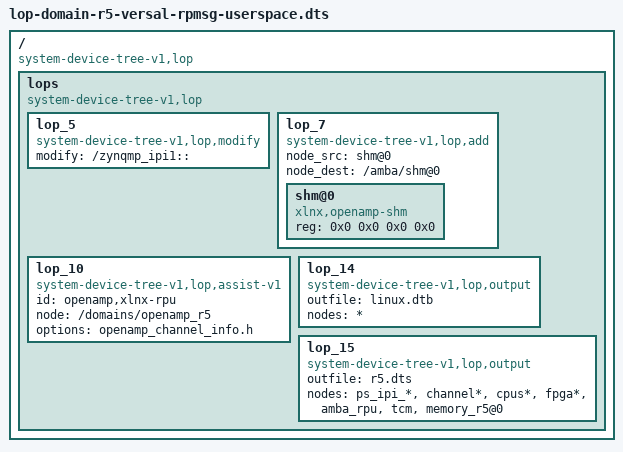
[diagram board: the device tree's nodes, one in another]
/*
 * Copyright (c) 2019,2020 Xilinx Inc. All rights reserved.
 *
 * Author:
 *       Bruce Ashfield <bruce.ashfield@xilinx.com>
 *
 * SPDX-License-Identifier: BSD-3-Clause
 */

/dts-v1/;

/ {
        compatible = "system-device-tree-v1,lop";
        lops {
                compatible = "system-device-tree-v1,lop";
                lop_5 {
                        // modify to "nothing", is a remove operation
                        compatible = "system-device-tree-v1,lop,modify";
                        modify = "/zynqmp_ipi1::";
                };

                lop_7 {
                        // node add
                        compatible = "system-device-tree-v1,lop,add";
                        node_src = "shm@0";
                        node_dest = "/amba/shm@0";
                        shm@0 {
                            compatible = "xlnx,openamp-shm";
                            #address-cells = <2>;
                            #size-cells = <2>;
                            ranges;
			    reg = <0x0 0x0 0x0 0x0>;
                        };
                  };
                  lop_10 {
                          // optionally execute a routine in a loaded module. If the routine
                          // isn't found, this is NOT a failure. Since we don't want to tightly
                          // couple these transforms and loaded modules
                          compatible = "system-device-tree-v1,lop,assist-v1";
                          id = "openamp,xlnx-rpu";
                          node = "/domains/openamp_r5";
                          options = "openamp_channel_info.h";
                  };

                  lop_14 {
                         compatible = "system-device-tree-v1,lop,output";
                         outfile = "linux.dtb";
                         // * is "all nodes"
                         nodes = "*";
                  };
                  lop_15 {
                         compatible = "system-device-tree-v1,lop,output";
                         outfile = "r5.dts";
                         // * is "all nodes"
                         nodes = "ps_ipi_*", "channel*", "cpus*","fpga*", "amba_rpu","tcm","memory_r5@0";
                  };

        };
};
